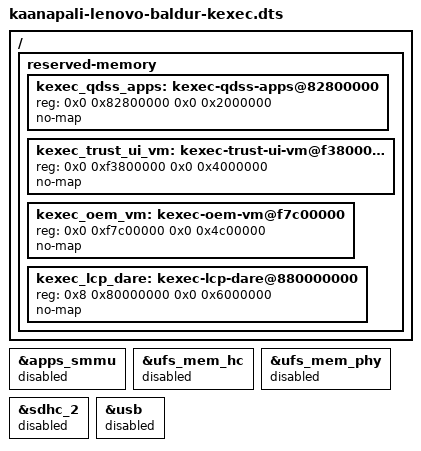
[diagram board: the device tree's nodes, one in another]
// SPDX-License-Identifier: BSD-3-Clause
/*
 * TB323FU ("baldur"), started by kexec from Android. Four regions inside
 * /memory are CMA pools that Android lends out (two to Gunyah VMs, two to
 * hardware) and may no longer be ours: keep out of them.
 */

#include "kaanapali-lenovo-baldur.dts"

/ {
	reserved-memory {
		/* vendor: qdss_apps_region, trace buffer for the QDSS hardware */
		kexec_qdss_apps: kexec-qdss-apps@82800000 {
			reg = <0x0 0x82800000 0x0 0x2000000>;
			no-map;
		};

		/* vendor: trust_ui_vm_region, lent to the trusted-UI VM */
		kexec_trust_ui_vm: kexec-trust-ui-vm@f3800000 {
			reg = <0x0 0xf3800000 0x0 0x4000000>;
			no-map;
		};

		/* vendor: oem_vm_region, lent to the OEM VM */
		kexec_oem_vm: kexec-oem-vm@f7c00000 {
			reg = <0x0 0xf7c00000 0x0 0x4c00000>;
			no-map;
		};

		/* vendor: lcp_dare_region */
		kexec_lcp_dare: kexec-lcp-dare@880000000 {
			reg = <0x8 0x80000000 0x0 0x6000000>;
			no-map;
		};
	};
};

/* reset after Android aborts on SMRs that Gunyah handed out */
&apps_smmu {
	status = "disabled";
};

/* behind the application SMMU, which is off here */
&ufs_mem_hc {
	status = "disabled";
};

&ufs_mem_phy {
	status = "disabled";
};

&sdhc_2 {
	status = "disabled";
};

/* USB sits behind the application SMMU too */
&usb {
	status = "disabled";
};
